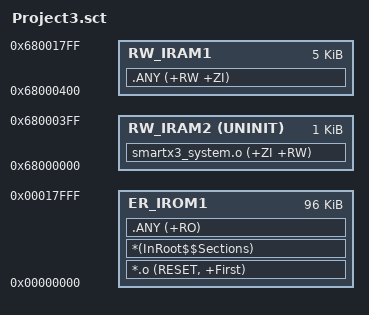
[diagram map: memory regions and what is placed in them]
; *************************************************************
; *** Scatter-Loading Description File generated by uVision ***
; *************************************************************

LR_IROM1 0x00000000 0x00018000  {    ; load region size_region
  ER_IROM1 0x00000000 0x00018000  {  ; load address = execution address
   *.o (RESET, +First)
   *(InRoot$$Sections)
   .ANY (+RO)
  }
  RW_IRAM1 0x68000400 0x00001400  {  ; RW data
   .ANY (+RW +ZI)
  }
  RW_IRAM2 0x68000000 UNINIT 0x00000400  {
    smartx3_system.o (+ZI +RW)
  }
}

